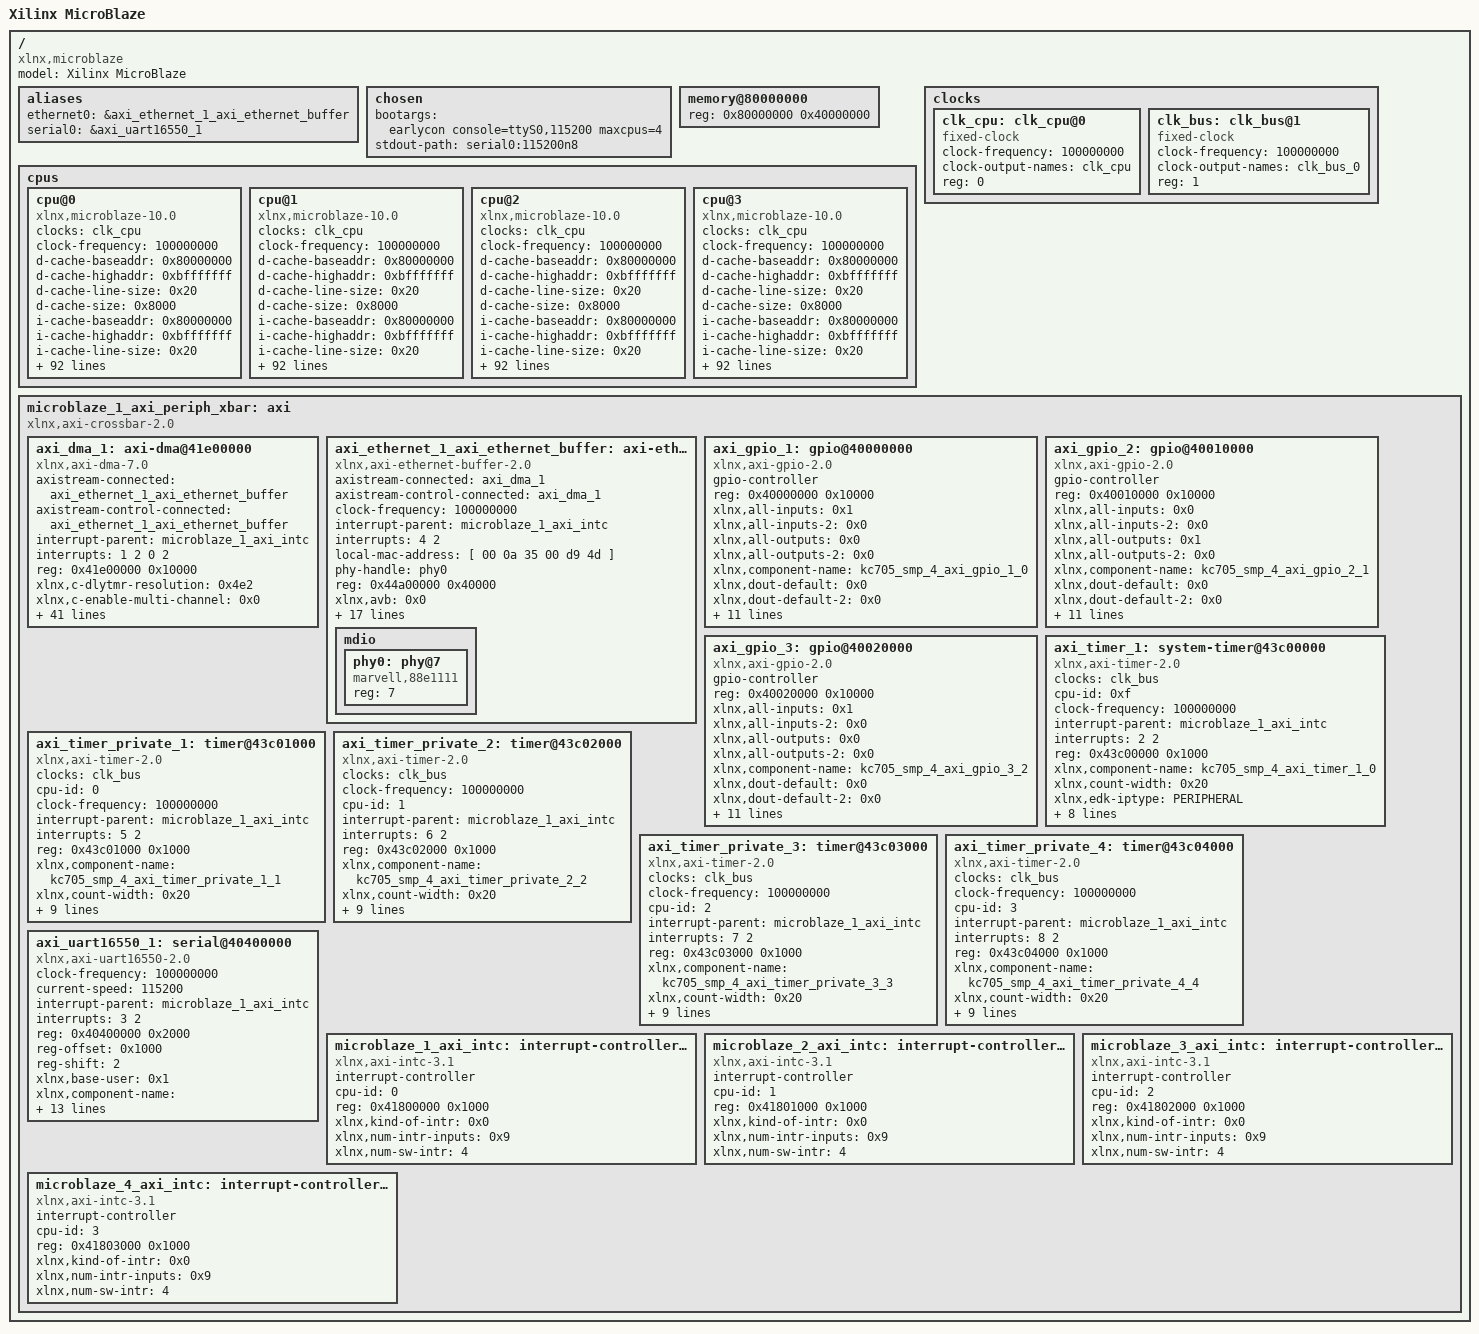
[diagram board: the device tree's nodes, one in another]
// SPDX-License-Identifier: GPL-2.0+
/*
 * dts file for Xilinx KC705 SMP hw design
 *
 * (C) Copyright 2007-2021 Xilinx, Inc.
 * (C) Copyright 2007-2012 Michal Simek
 * (C) Copyright 2007-2012 PetaLogix Qld Pty Ltd
 *
 * Michal SIMEK <monstr@monstr.eu>
 */

/dts-v1/;
/ {
	#address-cells = <1>;
	#size-cells = <1>;
	compatible = "xlnx,microblaze";
	model = "Xilinx MicroBlaze";
	aliases {
		ethernet0 = &axi_ethernet_1_axi_ethernet_buffer;
		serial0 = &axi_uart16550_1;
	} ;
	chosen {
		bootargs = "earlycon console=ttyS0,115200 maxcpus=4";
		stdout-path = "serial0:115200n8";
	} ;

	memory@80000000 {
		device_type = "memory";
		reg = < 0x80000000 0x40000000 >;
	} ;

	cpus {
		#address-cells = <1>;
		#size-cells = <0>;
		cpu@0 {
			clocks = <&clk_cpu>;
			clock-frequency = <100000000>;
			compatible = "xlnx,microblaze-10.0";
			d-cache-baseaddr = <0x80000000>;
			d-cache-highaddr = <0xbfffffff>;
			d-cache-line-size = <0x20>;
			d-cache-size = <0x8000>;
			device_type = "cpu";
			i-cache-baseaddr = <0x80000000>;
			i-cache-highaddr = <0xbfffffff>;
			i-cache-line-size = <0x20>;
			i-cache-size = <0x8000>;
			model = "xlnx,microblaze-10.0";
			reg = <0>;
			timebase-frequency = <100000000>;
			xlnx,addr-tag-bits = <0xf>;
			xlnx,allow-dcache-wr = <0x1>;
			xlnx,allow-icache-wr = <0x1>;
			xlnx,area-optimized = <0x0>;
			xlnx,async-interrupt = <0x1>;
			xlnx,avoid-primitives = <0x0>;
			xlnx,base-vectors = <0x0>;
			xlnx,branch-target-cache-size = <0x0>;
			xlnx,cache-byte-size = <0x8000>;
			xlnx,component-name = "kc705_smp_4_microblaze_1_0";
			xlnx,d-axi = <0x1>;
			xlnx,d-lmb = <0x1>;
			xlnx,data-size = <0x20>;
			xlnx,dcache-addr-tag = <0xf>;
			xlnx,dcache-always-used = <0x1>;
			xlnx,dcache-byte-size = <0x8000>;
			xlnx,dcache-data-width = <0x0>;
			xlnx,dcache-force-tag-lutram = <0x0>;
			xlnx,dcache-line-len = <0x8>;
			xlnx,dcache-use-writeback = <0x0>;
			xlnx,dcache-victims = <0x0>;
			xlnx,debug-enabled = <0x1>;
			xlnx,div-zero-exception = <0x1>;
			xlnx,dynamic-bus-sizing = <0x0>;
			xlnx,ecc-use-ce-exception = <0x0>;
			xlnx,edge-is-positive = <0x0>;
			xlnx,edk-iptype = "PROCESSOR";
			xlnx,edk-special = "microblaze";
			xlnx,enable-discrete-ports = <0x1>;
			xlnx,endianness = <0x1>;
			xlnx,family = "kintex7";
			xlnx,fault-tolerant = <0x0>;
			xlnx,fpu-exception = <0x1>;
			xlnx,freq = <0x5f5e100>;
			xlnx,fsl-exception = <0x0>;
			xlnx,fsl-links = <0x0>;
			xlnx,g-template-list = <0x0>;
			xlnx,g-use-exceptions = <0x1>;
			xlnx,i-axi = <0x0>;
			xlnx,i-lmb = <0x1>;
			xlnx,icache-always-used = <0x1>;
			xlnx,icache-data-width = <0x0>;
			xlnx,icache-force-tag-lutram = <0x0>;
			xlnx,icache-line-len = <0x8>;
			xlnx,icache-streams = <0x0>;
			xlnx,icache-victims = <0x0>;
			xlnx,ill-opcode-exception = <0x1>;
			xlnx,instance = "kc705_smp_4_microblaze_1_0";
			xlnx,interconnect = <0x3>;
			xlnx,interrupt-is-edge = <0x0>;
			xlnx,lockstep-select = <0x0>;
			xlnx,lockstep-slave = <0x0>;
			xlnx,mmu-dtlb-size = <0x4>;
			xlnx,mmu-itlb-size = <0x2>;
			xlnx,mmu-privileged-instr = <0x0>;
			xlnx,mmu-tlb-access = <0x3>;
			xlnx,mmu-zones = <0x2>;
			xlnx,number-of-pc-brk = <0x1>;
			xlnx,number-of-rd-addr-brk = <0x0>;
			xlnx,number-of-wr-addr-brk = <0x0>;
			xlnx,opcode-0x0-illegal = <0x1>;
			xlnx,optimization = <0x0>;
			xlnx,pc-width = <0x20>;
			xlnx,pvr = <0x2>;
			xlnx,pvr-user1 = <0x0>;
			xlnx,pvr-user2 = <0x0>;
			xlnx,reset-msr = <0x0>;
			xlnx,sco = <0x0>;
			xlnx,trace = <0x0>;
			xlnx,unaligned-exceptions = <0x1>;
			xlnx,use-barrel = <0x1>;
			xlnx,use-branch-target-cache = <0x0>;
			xlnx,use-config-reset = <0x0>;
			xlnx,use-dcache = <0x1>;
			xlnx,use-div = <0x1>;
			xlnx,use-ext-brk = <0x0>;
			xlnx,use-ext-nm-brk = <0x0>;
			xlnx,use-extended-fsl-instr = <0x0>;
			xlnx,use-fpu = <0x2>;
			xlnx,use-hw-mul = <0x2>;
			xlnx,use-icache = <0x1>;
			xlnx,use-interrupt = <0x1>;
			xlnx,use-mmu = <0x3>;
			xlnx,use-msr-instr = <0x1>;
			xlnx,use-pcmp-instr = <0x1>;
			xlnx,use-reorder-instr = <0x1>;
			xlnx,use-stack-protection = <0x0>;
		} ;
		cpu@1 {
			clocks = <&clk_cpu>;
			clock-frequency = <100000000>;
			compatible = "xlnx,microblaze-10.0";
			d-cache-baseaddr = <0x80000000>;
			d-cache-highaddr = <0xbfffffff>;
			d-cache-line-size = <0x20>;
			d-cache-size = <0x8000>;
			device_type = "cpu";
			i-cache-baseaddr = <0x80000000>;
			i-cache-highaddr = <0xbfffffff>;
			i-cache-line-size = <0x20>;
			i-cache-size = <0x8000>;
			model = "xlnx,microblaze-10.0";
			reg = <1>;
			timebase-frequency = <100000000>;
			xlnx,addr-tag-bits = <0xf>;
			xlnx,allow-dcache-wr = <0x1>;
			xlnx,allow-icache-wr = <0x1>;
			xlnx,area-optimized = <0x0>;
			xlnx,async-interrupt = <0x1>;
			xlnx,avoid-primitives = <0x0>;
			xlnx,base-vectors = <0x0>;
			xlnx,branch-target-cache-size = <0x0>;
			xlnx,cache-byte-size = <0x8000>;
			xlnx,component-name = "kc705_smp_4_microblaze_1_0";
			xlnx,d-axi = <0x1>;
			xlnx,d-lmb = <0x1>;
			xlnx,data-size = <0x20>;
			xlnx,dcache-addr-tag = <0xf>;
			xlnx,dcache-always-used = <0x1>;
			xlnx,dcache-byte-size = <0x8000>;
			xlnx,dcache-data-width = <0x0>;
			xlnx,dcache-force-tag-lutram = <0x0>;
			xlnx,dcache-line-len = <0x8>;
			xlnx,dcache-use-writeback = <0x0>;
			xlnx,dcache-victims = <0x0>;
			xlnx,debug-enabled = <0x1>;
			xlnx,div-zero-exception = <0x1>;
			xlnx,dynamic-bus-sizing = <0x0>;
			xlnx,ecc-use-ce-exception = <0x0>;
			xlnx,edge-is-positive = <0x0>;
			xlnx,edk-iptype = "PROCESSOR";
			xlnx,edk-special = "microblaze";
			xlnx,enable-discrete-ports = <0x1>;
			xlnx,endianness = <0x1>;
			xlnx,family = "kintex7";
			xlnx,fault-tolerant = <0x0>;
			xlnx,fpu-exception = <0x1>;
			xlnx,freq = <0x5f5e100>;
			xlnx,fsl-exception = <0x0>;
			xlnx,fsl-links = <0x0>;
			xlnx,g-template-list = <0x0>;
			xlnx,g-use-exceptions = <0x1>;
			xlnx,i-axi = <0x0>;
			xlnx,i-lmb = <0x1>;
			xlnx,icache-always-used = <0x1>;
			xlnx,icache-data-width = <0x0>;
			xlnx,icache-force-tag-lutram = <0x0>;
			xlnx,icache-line-len = <0x8>;
			xlnx,icache-streams = <0x0>;
			xlnx,icache-victims = <0x0>;
			xlnx,ill-opcode-exception = <0x1>;
			xlnx,instance = "kc705_smp_4_microblaze_1_0";
			xlnx,interconnect = <0x3>;
			xlnx,interrupt-is-edge = <0x0>;
			xlnx,lockstep-select = <0x0>;
			xlnx,lockstep-slave = <0x0>;
			xlnx,mmu-dtlb-size = <0x4>;
			xlnx,mmu-itlb-size = <0x2>;
			xlnx,mmu-privileged-instr = <0x0>;
			xlnx,mmu-tlb-access = <0x3>;
			xlnx,mmu-zones = <0x2>;
			xlnx,number-of-pc-brk = <0x1>;
			xlnx,number-of-rd-addr-brk = <0x0>;
			xlnx,number-of-wr-addr-brk = <0x0>;
			xlnx,opcode-0x0-illegal = <0x1>;
			xlnx,optimization = <0x0>;
			xlnx,pc-width = <0x20>;
			xlnx,pvr = <0x2>;
			xlnx,pvr-user1 = <0x1>;
			xlnx,pvr-user2 = <0x0>;
			xlnx,reset-msr = <0x0>;
			xlnx,sco = <0x0>;
			xlnx,trace = <0x0>;
			xlnx,unaligned-exceptions = <0x1>;
			xlnx,use-barrel = <0x1>;
			xlnx,use-branch-target-cache = <0x0>;
			xlnx,use-config-reset = <0x0>;
			xlnx,use-dcache = <0x1>;
			xlnx,use-div = <0x1>;
			xlnx,use-ext-brk = <0x0>;
			xlnx,use-ext-nm-brk = <0x0>;
			xlnx,use-extended-fsl-instr = <0x0>;
			xlnx,use-fpu = <0x2>;
			xlnx,use-hw-mul = <0x2>;
			xlnx,use-icache = <0x1>;
			xlnx,use-interrupt = <0x1>;
			xlnx,use-mmu = <0x3>;
			xlnx,use-msr-instr = <0x1>;
			xlnx,use-pcmp-instr = <0x1>;
			xlnx,use-reorder-instr = <0x1>;
			xlnx,use-stack-protection = <0x0>;
		} ;
		cpu@2 {
			clocks = <&clk_cpu>;
			clock-frequency = <100000000>;
			compatible = "xlnx,microblaze-10.0";
			d-cache-baseaddr = <0x80000000>;
			d-cache-highaddr = <0xbfffffff>;
			d-cache-line-size = <0x20>;
			d-cache-size = <0x8000>;
			device_type = "cpu";
			i-cache-baseaddr = <0x80000000>;
			i-cache-highaddr = <0xbfffffff>;
			i-cache-line-size = <0x20>;
			i-cache-size = <0x8000>;
			model = "xlnx,microblaze-10.0";
			reg = <2>;
			timebase-frequency = <100000000>;
			xlnx,addr-tag-bits = <0xf>;
			xlnx,allow-dcache-wr = <0x1>;
			xlnx,allow-icache-wr = <0x1>;
			xlnx,area-optimized = <0x0>;
			xlnx,async-interrupt = <0x1>;
			xlnx,avoid-primitives = <0x0>;
			xlnx,base-vectors = <0x0>;
			xlnx,branch-target-cache-size = <0x0>;
			xlnx,cache-byte-size = <0x8000>;
			xlnx,component-name = "kc705_smp_4_microblaze_1_0";
			xlnx,d-axi = <0x1>;
			xlnx,d-lmb = <0x1>;
			xlnx,data-size = <0x20>;
			xlnx,dcache-addr-tag = <0xf>;
			xlnx,dcache-always-used = <0x1>;
			xlnx,dcache-byte-size = <0x8000>;
			xlnx,dcache-data-width = <0x0>;
			xlnx,dcache-force-tag-lutram = <0x0>;
			xlnx,dcache-line-len = <0x8>;
			xlnx,dcache-use-writeback = <0x0>;
			xlnx,dcache-victims = <0x0>;
			xlnx,debug-enabled = <0x1>;
			xlnx,div-zero-exception = <0x1>;
			xlnx,dynamic-bus-sizing = <0x0>;
			xlnx,ecc-use-ce-exception = <0x0>;
			xlnx,edge-is-positive = <0x0>;
			xlnx,edk-iptype = "PROCESSOR";
			xlnx,edk-special = "microblaze";
			xlnx,enable-discrete-ports = <0x1>;
			xlnx,endianness = <0x1>;
			xlnx,family = "kintex7";
			xlnx,fault-tolerant = <0x0>;
			xlnx,fpu-exception = <0x1>;
			xlnx,freq = <0x5f5e100>;
			xlnx,fsl-exception = <0x0>;
			xlnx,fsl-links = <0x0>;
			xlnx,g-template-list = <0x0>;
			xlnx,g-use-exceptions = <0x1>;
			xlnx,i-axi = <0x0>;
			xlnx,i-lmb = <0x1>;
			xlnx,icache-always-used = <0x1>;
			xlnx,icache-data-width = <0x0>;
			xlnx,icache-force-tag-lutram = <0x0>;
			xlnx,icache-line-len = <0x8>;
			xlnx,icache-streams = <0x0>;
			xlnx,icache-victims = <0x0>;
			xlnx,ill-opcode-exception = <0x1>;
			xlnx,instance = "kc705_smp_4_microblaze_1_0";
			xlnx,interconnect = <0x3>;
			xlnx,interrupt-is-edge = <0x0>;
			xlnx,lockstep-select = <0x0>;
			xlnx,lockstep-slave = <0x0>;
			xlnx,mmu-dtlb-size = <0x4>;
			xlnx,mmu-itlb-size = <0x2>;
			xlnx,mmu-privileged-instr = <0x0>;
			xlnx,mmu-tlb-access = <0x3>;
			xlnx,mmu-zones = <0x2>;
			xlnx,number-of-pc-brk = <0x1>;
			xlnx,number-of-rd-addr-brk = <0x0>;
			xlnx,number-of-wr-addr-brk = <0x0>;
			xlnx,opcode-0x0-illegal = <0x1>;
			xlnx,optimization = <0x0>;
			xlnx,pc-width = <0x20>;
			xlnx,pvr = <0x2>;
			xlnx,pvr-user1 = <0x2>;
			xlnx,pvr-user2 = <0x0>;
			xlnx,reset-msr = <0x0>;
			xlnx,sco = <0x0>;
			xlnx,trace = <0x0>;
			xlnx,unaligned-exceptions = <0x1>;
			xlnx,use-barrel = <0x1>;
			xlnx,use-branch-target-cache = <0x0>;
			xlnx,use-config-reset = <0x0>;
			xlnx,use-dcache = <0x1>;
			xlnx,use-div = <0x1>;
			xlnx,use-ext-brk = <0x0>;
			xlnx,use-ext-nm-brk = <0x0>;
			xlnx,use-extended-fsl-instr = <0x0>;
			xlnx,use-fpu = <0x2>;
			xlnx,use-hw-mul = <0x2>;
			xlnx,use-icache = <0x1>;
			xlnx,use-interrupt = <0x1>;
			xlnx,use-mmu = <0x3>;
			xlnx,use-msr-instr = <0x1>;
			xlnx,use-pcmp-instr = <0x1>;
			xlnx,use-reorder-instr = <0x1>;
			xlnx,use-stack-protection = <0x0>;
		} ;
		cpu@3 {
			clocks = <&clk_cpu>;
			clock-frequency = <100000000>;
			compatible = "xlnx,microblaze-10.0";
			d-cache-baseaddr = <0x80000000>;
			d-cache-highaddr = <0xbfffffff>;
			d-cache-line-size = <0x20>;
			d-cache-size = <0x8000>;
			device_type = "cpu";
			i-cache-baseaddr = <0x80000000>;
			i-cache-highaddr = <0xbfffffff>;
			i-cache-line-size = <0x20>;
			i-cache-size = <0x8000>;
			model = "xlnx,microblaze-10.0";
			reg = <3>;
			timebase-frequency = <100000000>;
			xlnx,addr-tag-bits = <0xf>;
			xlnx,allow-dcache-wr = <0x1>;
			xlnx,allow-icache-wr = <0x1>;
			xlnx,area-optimized = <0x0>;
			xlnx,async-interrupt = <0x1>;
			xlnx,avoid-primitives = <0x0>;
			xlnx,base-vectors = <0x0>;
			xlnx,branch-target-cache-size = <0x0>;
			xlnx,cache-byte-size = <0x8000>;
			xlnx,component-name = "kc705_smp_4_microblaze_1_0";
			xlnx,d-axi = <0x1>;
			xlnx,d-lmb = <0x1>;
			xlnx,data-size = <0x20>;
			xlnx,dcache-addr-tag = <0xf>;
			xlnx,dcache-always-used = <0x1>;
			xlnx,dcache-byte-size = <0x8000>;
			xlnx,dcache-data-width = <0x0>;
			xlnx,dcache-force-tag-lutram = <0x0>;
			xlnx,dcache-line-len = <0x8>;
			xlnx,dcache-use-writeback = <0x0>;
			xlnx,dcache-victims = <0x0>;
			xlnx,debug-enabled = <0x1>;
			xlnx,div-zero-exception = <0x1>;
			xlnx,dynamic-bus-sizing = <0x0>;
			xlnx,ecc-use-ce-exception = <0x0>;
			xlnx,edge-is-positive = <0x0>;
			xlnx,edk-iptype = "PROCESSOR";
			xlnx,edk-special = "microblaze";
			xlnx,enable-discrete-ports = <0x1>;
			xlnx,endianness = <0x1>;
			xlnx,family = "kintex7";
			xlnx,fault-tolerant = <0x0>;
			xlnx,fpu-exception = <0x1>;
			xlnx,freq = <0x5f5e100>;
			xlnx,fsl-exception = <0x0>;
			xlnx,fsl-links = <0x0>;
			xlnx,g-template-list = <0x0>;
			xlnx,g-use-exceptions = <0x1>;
			xlnx,i-axi = <0x0>;
			xlnx,i-lmb = <0x1>;
			xlnx,icache-always-used = <0x1>;
			xlnx,icache-data-width = <0x0>;
			xlnx,icache-force-tag-lutram = <0x0>;
			xlnx,icache-line-len = <0x8>;
			xlnx,icache-streams = <0x0>;
			xlnx,icache-victims = <0x0>;
			xlnx,ill-opcode-exception = <0x1>;
			xlnx,instance = "kc705_smp_4_microblaze_1_0";
			xlnx,interconnect = <0x3>;
			xlnx,interrupt-is-edge = <0x0>;
			xlnx,lockstep-select = <0x0>;
			xlnx,lockstep-slave = <0x0>;
			xlnx,mmu-dtlb-size = <0x4>;
			xlnx,mmu-itlb-size = <0x2>;
			xlnx,mmu-privileged-instr = <0x0>;
			xlnx,mmu-tlb-access = <0x3>;
			xlnx,mmu-zones = <0x2>;
			xlnx,number-of-pc-brk = <0x1>;
			xlnx,number-of-rd-addr-brk = <0x0>;
			xlnx,number-of-wr-addr-brk = <0x0>;
			xlnx,opcode-0x0-illegal = <0x1>;
			xlnx,optimization = <0x0>;
			xlnx,pc-width = <0x20>;
			xlnx,pvr = <0x2>;
			xlnx,pvr-user1 = <0x3>;
			xlnx,pvr-user2 = <0x0>;
			xlnx,reset-msr = <0x0>;
			xlnx,sco = <0x0>;
			xlnx,trace = <0x0>;
			xlnx,unaligned-exceptions = <0x1>;
			xlnx,use-barrel = <0x1>;
			xlnx,use-branch-target-cache = <0x0>;
			xlnx,use-config-reset = <0x0>;
			xlnx,use-dcache = <0x1>;
			xlnx,use-div = <0x1>;
			xlnx,use-ext-brk = <0x0>;
			xlnx,use-ext-nm-brk = <0x0>;
			xlnx,use-extended-fsl-instr = <0x0>;
			xlnx,use-fpu = <0x2>;
			xlnx,use-hw-mul = <0x2>;
			xlnx,use-icache = <0x1>;
			xlnx,use-interrupt = <0x1>;
			xlnx,use-mmu = <0x3>;
			xlnx,use-msr-instr = <0x1>;
			xlnx,use-pcmp-instr = <0x1>;
			xlnx,use-reorder-instr = <0x1>;
			xlnx,use-stack-protection = <0x0>;
		} ;
	} ;

	clocks {
		#address-cells = <0x1>;
		#size-cells = <0x0>;

		clk_cpu: clk_cpu@0 {
			#clock-cells = <0>;
			clock-frequency = <100000000>;
			clock-output-names = "clk_cpu";
			compatible = "fixed-clock";
			reg = <0>;
		};
		clk_bus: clk_bus@1 {
			#clock-cells = <0>;
			clock-frequency = <100000000>;
			clock-output-names = "clk_bus_0";
			compatible = "fixed-clock";
			reg = <1>;
		};
	};

	microblaze_1_axi_periph_xbar: axi {
		#address-cells = <1>;
		#size-cells = <1>;
		compatible = "xlnx,axi-crossbar-2.0", "simple-bus";
		ranges ;
		axi_dma_1: axi-dma@41e00000 {
			axistream-connected = <&axi_ethernet_1_axi_ethernet_buffer>;
			axistream-control-connected = <&axi_ethernet_1_axi_ethernet_buffer>;
			compatible = "xlnx,axi-dma-7.0", "xlnx,axi-dma-1.00.a";
			interrupt-parent = <&microblaze_1_axi_intc>;
			interrupts = < 1 2 0 2 >;
			reg = < 0x41e00000 0x10000 >;
			xlnx,c-dlytmr-resolution = <0x4e2>;
			xlnx,c-enable-multi-channel = <0x0>;
			xlnx,c-include-mm2s = <0x1>;
			xlnx,c-include-mm2s-dre = <0x1>;
			xlnx,c-include-mm2s-sf = <0x1>;
			xlnx,c-include-s2mm = <0x1>;
			xlnx,c-include-s2mm-dre = <0x1>;
			xlnx,c-include-s2mm-sf = <0x1>;
			xlnx,c-include-sg = <0x1>;
			xlnx,c-m-axi-mm2s-data-width = <0x20>;
			xlnx,c-m-axi-s2mm-data-width = <0x20>;
			xlnx,c-m-axis-mm2s-tdata-width = <0x20>;
			xlnx,c-mm2s-burst-size = <0x10>;
			xlnx,c-num-mm2s-channels = <0x1>;
			xlnx,c-num-s2mm-channels = <0x1>;
			xlnx,c-prmry-is-aclk-async = <0x0>;
			xlnx,c-s-axis-s2mm-tdata-width = <0x20>;
			xlnx,c-s2mm-burst-size = <0x10>;
			xlnx,c-sg-include-desc-queue = <0x1>;
			xlnx,c-sg-include-stscntrl-strm = <0x1>;
			xlnx,c-sg-length-width = <0x10>;
			xlnx,c-sg-use-stsapp-length = <0x1>;
			xlnx,component-name = "kc705_smp_4_axi_dma_1_0";
			xlnx,dlytmr-resolution = <0x4e2>;
			xlnx,edk-iptype = "PERIPHERAL";
			xlnx,enable-multi-channel = <0x0>;
			xlnx,family = "kintex7";
			xlnx,include-mm2s = <0x1>;
			xlnx,include-mm2s-dre = <0x1>;
			xlnx,include-mm2s-sf = <0x1>;
			xlnx,include-s2mm = <0x1>;
			xlnx,include-s2mm-dre = <0x1>;
			xlnx,include-s2mm-sf = <0x1>;
			xlnx,include-sg = <0x1>;
			xlnx,mm2s-burst-size = <0x10>;
			xlnx,num-mm2s-channels = <0x1>;
			xlnx,num-s2mm-channels = <0x1>;
			xlnx,prmry-is-aclk-async = <0x0>;
			xlnx,s2mm-burst-size = <0x10>;
			xlnx,sg-include-desc-queue = <0x1>;
			xlnx,sg-include-stscntrl-strm = <0x1>;
			xlnx,sg-length-width = <0x10>;
			xlnx,sg-use-stsapp-length = <0x1>;
		} ;
		axi_ethernet_1_axi_ethernet_buffer: axi-ethernet@44a00000 {
			axistream-connected = <&axi_dma_1>;
			axistream-control-connected = <&axi_dma_1>;
			clock-frequency = <100000000>;
			compatible = "xlnx,axi-ethernet-buffer-2.0", "xlnx,axi-ethernet-3.01.a", "xlnx,axi-ethernet-1.00.a";
			device_type = "network";
			interrupt-parent = <&microblaze_1_axi_intc>;
			interrupts = < 4 2 >;
			local-mac-address = [ 00 0a 35 00 d9 4d ];
			phy-handle = <&phy0>;
			reg = < 0x44a00000 0x40000 >;
			xlnx,avb = <0x0>;
			xlnx,halfdup = <0x0>;
			xlnx,include-io = "1";
			xlnx,mcast-extend = <0x0>;
			xlnx,phy-type = <0x1>;
			xlnx,phyaddr = <0x1>;
			xlnx,rxcsum = <0x0>;
			xlnx,rxmem = <0x1000>;
			xlnx,rxvlan-strp = <0x0>;
			xlnx,rxvlan-tag = <0x0>;
			xlnx,rxvlan-tran = <0x0>;
			xlnx,stats = <0x0>;
			xlnx,txcsum = <0x0>;
			xlnx,txmem = <0x1000>;
			xlnx,txvlan-strp = <0x0>;
			xlnx,txvlan-tag = <0x0>;
			xlnx,txvlan-tran = <0x0>;
			xlnx,type = <0x1>;
			mdio {
				#address-cells = <1>;
				#size-cells = <0>;
				phy0: phy@7 {
					compatible = "marvell,88e1111";
					device_type = "ethernet-phy";
					reg = <7>;
				} ;
			} ;
		} ;
		axi_gpio_1: gpio@40000000 {
			#gpio-cells = <2>;
			compatible = "xlnx,axi-gpio-2.0", "xlnx,xps-gpio-1.00.a";
			gpio-controller ;
			reg = < 0x40000000 0x10000 >;
			xlnx,all-inputs = <0x1>;
			xlnx,all-inputs-2 = <0x0>;
			xlnx,all-outputs = <0x0>;
			xlnx,all-outputs-2 = <0x0>;
			xlnx,component-name = "kc705_smp_4_axi_gpio_1_0";
			xlnx,dout-default = <0x0>;
			xlnx,dout-default-2 = <0x0>;
			xlnx,edk-iptype = "PERIPHERAL";
			xlnx,family = "kintex7";
			xlnx,gpio-board-interface = "dip_switches_4bits";
			xlnx,gpio-width = <0x4>;
			xlnx,gpio2-board-interface = "Custom";
			xlnx,gpio2-width = <0x20>;
			xlnx,interrupt-present = <0x0>;
			xlnx,is-dual = <0x0>;
			xlnx,tri-default = <0xffffffff>;
			xlnx,tri-default-2 = <0xffffffff>;
			xlnx,use-board-flow = <0x1>;
		} ;
		axi_gpio_2: gpio@40010000 {
			#gpio-cells = <2>;
			compatible = "xlnx,axi-gpio-2.0", "xlnx,xps-gpio-1.00.a";
			gpio-controller ;
			reg = < 0x40010000 0x10000 >;
			xlnx,all-inputs = <0x0>;
			xlnx,all-inputs-2 = <0x0>;
			xlnx,all-outputs = <0x1>;
			xlnx,all-outputs-2 = <0x0>;
			xlnx,component-name = "kc705_smp_4_axi_gpio_2_1";
			xlnx,dout-default = <0x0>;
			xlnx,dout-default-2 = <0x0>;
			xlnx,edk-iptype = "PERIPHERAL";
			xlnx,family = "kintex7";
			xlnx,gpio-board-interface = "led_8bits";
			xlnx,gpio-width = <0x8>;
			xlnx,gpio2-board-interface = "Custom";
			xlnx,gpio2-width = <0x20>;
			xlnx,interrupt-present = <0x0>;
			xlnx,is-dual = <0x0>;
			xlnx,tri-default = <0xffffffff>;
			xlnx,tri-default-2 = <0xffffffff>;
			xlnx,use-board-flow = <0x1>;
		} ;
		axi_gpio_3: gpio@40020000 {
			#gpio-cells = <2>;
			compatible = "xlnx,axi-gpio-2.0", "xlnx,xps-gpio-1.00.a";
			gpio-controller ;
			reg = < 0x40020000 0x10000 >;
			xlnx,all-inputs = <0x1>;
			xlnx,all-inputs-2 = <0x0>;
			xlnx,all-outputs = <0x0>;
			xlnx,all-outputs-2 = <0x0>;
			xlnx,component-name = "kc705_smp_4_axi_gpio_3_2";
			xlnx,dout-default = <0x0>;
			xlnx,dout-default-2 = <0x0>;
			xlnx,edk-iptype = "PERIPHERAL";
			xlnx,family = "kintex7";
			xlnx,gpio-board-interface = "push_buttons_5bits";
			xlnx,gpio-width = <0x5>;
			xlnx,gpio2-board-interface = "Custom";
			xlnx,gpio2-width = <0x20>;
			xlnx,interrupt-present = <0x0>;
			xlnx,is-dual = <0x0>;
			xlnx,tri-default = <0xffffffff>;
			xlnx,tri-default-2 = <0xffffffff>;
			xlnx,use-board-flow = <0x1>;
		} ;
		axi_timer_1: system-timer@43c00000 {
			clocks = <&clk_bus>;
			cpu-id = <0xf>;
			clock-frequency = <100000000>;
			compatible = "xlnx,axi-timer-2.0", "xlnx,xps-timer-1.00.a";
			interrupt-parent = <&microblaze_1_axi_intc>;
			interrupts = < 2 2 >;
			reg = < 0x43c00000 0x1000 >;
			xlnx,component-name = "kc705_smp_4_axi_timer_1_0";
			xlnx,count-width = <0x20>;
			xlnx,edk-iptype = "PERIPHERAL";
			xlnx,enable-timer2 = <0x1>;
			xlnx,family = "kintex7";
			xlnx,gen0-assert = <0x1>;
			xlnx,gen1-assert = <0x1>;
			xlnx,mode-64bit = <0x0>;
			xlnx,one-timer-only = <0x0>;
			xlnx,trig0-assert = <0x1>;
			xlnx,trig1-assert = <0x1>;
		} ;
		axi_timer_private_1: timer@43c01000 {
			clocks = <&clk_bus>;
			cpu-id = <0>;
			clock-frequency = <100000000>;
			compatible = "xlnx,axi-timer-2.0", "xlnx,xps-timer-1.00.a";
			interrupt-parent = <&microblaze_1_axi_intc>;
			interrupts = < 5 2 >;
			reg = < 0x43c01000 0x1000 >;
			xlnx,component-name = "kc705_smp_4_axi_timer_private_1_1";
			xlnx,count-width = <0x20>;
			xlnx,edk-iptype = "PERIPHERAL";
			xlnx,enable-timer2 = <0x0>;
			xlnx,family = "kintex7";
			xlnx,gen0-assert = <0x1>;
			xlnx,gen1-assert = <0x1>;
			xlnx,mode-64bit = <0x0>;
			xlnx,one-timer-only = <0x1>;
			xlnx,trig0-assert = <0x1>;
			xlnx,trig1-assert = <0x1>;
		} ;
		axi_timer_private_2: timer@43c02000 {
			clocks = <&clk_bus>;
			clock-frequency = <100000000>;
			cpu-id = <1>;
			compatible = "xlnx,axi-timer-2.0", "xlnx,xps-timer-1.00.a";
			interrupt-parent = <&microblaze_1_axi_intc>;
			interrupts = < 6 2 >;
			reg = < 0x43c02000 0x1000 >;
			xlnx,component-name = "kc705_smp_4_axi_timer_private_2_2";
			xlnx,count-width = <0x20>;
			xlnx,edk-iptype = "PERIPHERAL";
			xlnx,enable-timer2 = <0x0>;
			xlnx,family = "kintex7";
			xlnx,gen0-assert = <0x1>;
			xlnx,gen1-assert = <0x1>;
			xlnx,mode-64bit = <0x0>;
			xlnx,one-timer-only = <0x1>;
			xlnx,trig0-assert = <0x1>;
			xlnx,trig1-assert = <0x1>;
		} ;
		axi_timer_private_3: timer@43c03000 {
			clocks = <&clk_bus>;
			clock-frequency = <100000000>;
			cpu-id = <2>;
			compatible = "xlnx,axi-timer-2.0", "xlnx,xps-timer-1.00.a";
			interrupt-parent = <&microblaze_1_axi_intc>;
			interrupts = < 7 2 >;
			reg = < 0x43c03000 0x1000 >;
			xlnx,component-name = "kc705_smp_4_axi_timer_private_3_3";
			xlnx,count-width = <0x20>;
			xlnx,edk-iptype = "PERIPHERAL";
			xlnx,enable-timer2 = <0x0>;
			xlnx,family = "kintex7";
			xlnx,gen0-assert = <0x1>;
			xlnx,gen1-assert = <0x1>;
			xlnx,mode-64bit = <0x0>;
			xlnx,one-timer-only = <0x1>;
			xlnx,trig0-assert = <0x1>;
			xlnx,trig1-assert = <0x1>;
		} ;
		axi_timer_private_4: timer@43c04000 {
			clocks = <&clk_bus>;
			clock-frequency = <100000000>;
			cpu-id = <3>;
			compatible = "xlnx,axi-timer-2.0", "xlnx,xps-timer-1.00.a";
			interrupt-parent = <&microblaze_1_axi_intc>;
			interrupts = < 8 2 >;
			reg = < 0x43c04000 0x1000 >;
			xlnx,component-name = "kc705_smp_4_axi_timer_private_4_4";
			xlnx,count-width = <0x20>;
			xlnx,edk-iptype = "PERIPHERAL";
			xlnx,enable-timer2 = <0x0>;
			xlnx,family = "kintex7";
			xlnx,gen0-assert = <0x1>;
			xlnx,gen1-assert = <0x1>;
			xlnx,mode-64bit = <0x0>;
			xlnx,one-timer-only = <0x1>;
			xlnx,trig0-assert = <0x1>;
			xlnx,trig1-assert = <0x1>;
		} ;
		axi_uart16550_1: serial@40400000 {
			clock-frequency = <100000000>;
			compatible = "xlnx,axi-uart16550-2.0", "xlnx,xps-uart16550-2.00.a", "ns16550a";
			current-speed = <115200>;
			device_type = "serial";
			interrupt-parent = <&microblaze_1_axi_intc>;
			interrupts = < 3 2 >;
			reg = < 0x40400000 0x2000 >;
			reg-offset = <0x1000>;
			reg-shift = <2>;
			xlnx,base-user = <0x1>;
			xlnx,component-name = "kc705_smp_4_axi_uart16550_1_0";
			xlnx,edk-iptype = "PERIPHERAL";
			xlnx,external-xin-clk-hz = <0x17d7840>;
			xlnx,external-xin-clk-hz-d = <0x19>;
			xlnx,family = "kintex7";
			xlnx,has-external-rclk = <0x0>;
			xlnx,has-external-xin = <0x0>;
			xlnx,is-a-16550 = <0x1>;
			xlnx,s-axi-aclk-freq-hz-d = <0x64>;
			xlnx,uart-board-interface = "Custom";
			xlnx,use-board-flow = <0x0>;
			xlnx,use-modem-ports = <0x1>;
			xlnx,use-user-ports = <0x1>;
		} ;
		microblaze_1_axi_intc: interrupt-controller@41800000 {
			#interrupt-cells = <0x2>;
			compatible = "xlnx,axi-intc-3.1", "xlnx,xps-intc-1.00.a";
			interrupt-controller ;
			cpu-id = <0>;
			reg = < 0x41800000 0x1000 >;
			xlnx,kind-of-intr = <0x0>;
			xlnx,num-intr-inputs = <0x9>;
			xlnx,num-sw-intr = <4>;
		} ;
		microblaze_2_axi_intc: interrupt-controller@41801000 {
			#interrupt-cells = <0x2>;
			compatible = "xlnx,axi-intc-3.1", "xlnx,xps-intc-1.00.a";
			interrupt-controller ;
			cpu-id = <1>;
			reg = < 0x41801000 0x1000 >;
			xlnx,kind-of-intr = <0x0>;
			xlnx,num-intr-inputs = <0x9>;
			xlnx,num-sw-intr = <4>;
		} ;
		microblaze_3_axi_intc: interrupt-controller@41802000 {
			#interrupt-cells = <0x2>;
			compatible = "xlnx,axi-intc-3.1", "xlnx,xps-intc-1.00.a";
			interrupt-controller ;
			cpu-id = <2>;
			reg = < 0x41802000 0x1000 >;
			xlnx,kind-of-intr = <0x0>;
			xlnx,num-intr-inputs = <0x9>;
			xlnx,num-sw-intr = <4>;
		} ;
		microblaze_4_axi_intc: interrupt-controller@41803000 {
			#interrupt-cells = <0x2>;
			compatible = "xlnx,axi-intc-3.1", "xlnx,xps-intc-1.00.a";
			interrupt-controller ;
			cpu-id = <3>;
			reg = < 0x41803000 0x1000 >;
			xlnx,kind-of-intr = <0x0>;
			xlnx,num-intr-inputs = <0x9>;
			xlnx,num-sw-intr = <4>;
		} ;
	} ;
} ;
